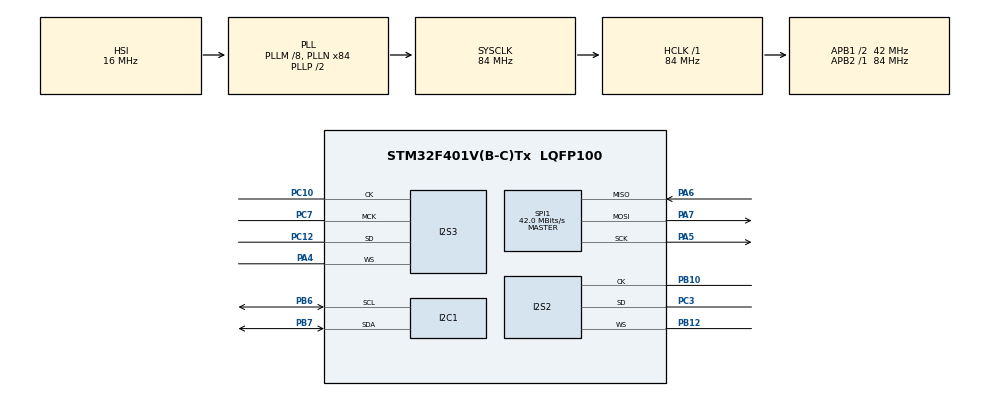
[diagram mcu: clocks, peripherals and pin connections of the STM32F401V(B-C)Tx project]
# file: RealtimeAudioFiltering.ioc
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Dma.Request0=SPI2_RX
Dma.Request1=SPI3_TX
Dma.SPI2_RX.0.Direction=DMA_PERIPH_TO_MEMORY
Dma.SPI2_RX.0.FIFOMode=DMA_FIFOMODE_DISABLE
Dma.SPI2_RX.0.Instance=DMA1_Stream3
Dma.SPI2_RX.0.MemDataAlignment=DMA_MDATAALIGN_HALFWORD
Dma.SPI2_RX.0.MemInc=DMA_MINC_ENABLE
Dma.SPI2_RX.0.Mode=DMA_CIRCULAR
Dma.SPI2_RX.0.PeriphDataAlignment=DMA_PDATAALIGN_HALFWORD
Dma.SPI2_RX.0.PeriphInc=DMA_PINC_DISABLE
Dma.SPI2_RX.0.Priority=DMA_PRIORITY_HIGH
Dma.SPI3_TX.1.Direction=DMA_MEMORY_TO_PERIPH
Dma.SPI3_TX.1.FIFOMode=DMA_FIFOMODE_DISABLE
Dma.SPI3_TX.1.Instance=DMA1_Stream5
Dma.SPI3_TX.1.MemDataAlignment=DMA_MDATAALIGN_HALFWORD
Dma.SPI3_TX.1.MemInc=DMA_MINC_ENABLE
Dma.SPI3_TX.1.Mode=DMA_CIRCULAR
Dma.SPI3_TX.1.PeriphDataAlignment=DMA_PDATAALIGN_HALFWORD
Dma.SPI3_TX.1.PeriphInc=DMA_PINC_DISABLE
Dma.SPI3_TX.1.Priority=DMA_PRIORITY_HIGH
I2S2.AudioFreq=I2S_AUDIOFREQ_48K
I2S2.CPOL=I2S_CPOL_LOW
I2S2.DataFormat=I2S_DATAFORMAT_24B
I2S2.ErrorAudioFreq=1.72 %
I2S2.FullDuplexMode=I2S_FULLDUPLEXMODE_DISABLE
I2S2.Instance=SPI$Index
I2S2.Mode=I2S_MODE_SLAVE_RX
I2S2.RealAudioFreq=48.828 KHz
I2S2.Standard=I2S_STANDARD_MSB
I2S2.VirtualMode=I2S_MODE_SLAVE
I2S3.AudioFreq=I2S_AUDIOFREQ_48K
I2S3.DataFormat=I2S_DATAFORMAT_24B
I2S3.ErrorAudioFreq=1.72 %
I2S3.FullDuplexMode=I2S_FULLDUPLEXMODE_DISABLE
I2S3.Instance=SPI$Index
I2S3.RealAudioFreq=48.828 KHz
I2S3.VirtualMode=I2S_MODE_MASTER
Mcu.Family=STM32F4
Mcu.Name=STM32F401V(B-C)Tx
Mcu.Package=LQFP100
NVIC.DMA1_Stream3_IRQn=true\:0\:0\:false\:false\:true\:false\:true\:true
NVIC.DMA1_Stream5_IRQn=true\:0\:0\:false\:false\:true\:false\:true\:true
NVIC.PriorityGroup=NVIC_PRIORITYGROUP_4
PA13.Mode=Serial_Wire
PA13.Signal=SYS_JTMS-SWDIO
PA14.Mode=Serial_Wire
PA14.Signal=SYS_JTCK-SWCLK
PA4.GPIO_Speed=GPIO_SPEED_FREQ_HIGH
PA4.Mode=Half_Duplex_Master
PA4.Signal=I2S3_WS
PA5.Mode=Full_Duplex_Master
PA5.Signal=SPI1_SCK
PA6.Mode=Full_Duplex_Master
PA6.Signal=SPI1_MISO
PA7.Mode=Full_Duplex_Master
PA7.Signal=SPI1_MOSI
PB10.GPIO_Speed=GPIO_SPEED_FREQ_HIGH
PB10.Mode=Half_Duplex_Slave
PB10.Signal=I2S2_CK
PB12.GPIO_Speed=GPIO_SPEED_FREQ_HIGH
PB12.Mode=Half_Duplex_Slave
PB12.Signal=I2S2_WS
PB6.Mode=I2C
PB6.Signal=I2C1_SCL
PB7.Mode=I2C
PB7.Signal=I2C1_SDA
PC10.GPIO_Speed=GPIO_SPEED_FREQ_HIGH
PC10.Mode=Half_Duplex_Master
PC10.Signal=I2S3_CK
PC12.GPIO_Speed=GPIO_SPEED_FREQ_HIGH
PC12.Mode=Half_Duplex_Master
PC12.Signal=I2S3_SD
PC3.GPIO_Speed=GPIO_SPEED_FREQ_HIGH
PC3.Mode=Half_Duplex_Slave
PC3.Signal=I2S2_SD
PC7.GPIO_Speed=GPIO_SPEED_FREQ_HIGH
PC7.Mode=Master_Clock_Activated
PC7.Signal=I2S3_MCK
PDM2PCM.CHANNEL1_bit_order=PDM_FILTER_BIT_ORDER_LSB
PDM2PCM.CHANNEL1_endianness=PDM_FILTER_ENDIANNESS_BE
PDM2PCM.CHANNEL1_high_pass_tap=2122358088
PDM2PCM.CHANNEL1_in_ptr_channels=1
PDM2PCM.CHANNEL1_mic_gain=0
PDM2PCM.CHANNEL1_out_ptr_channels=1
PH0\ -\ OSC_IN.Mode=HSE-External-Oscillator
PH0\ -\ OSC_IN.Signal=RCC_OSC_IN
PH1\ -\ OSC_OUT.Mode=HSE-External-Oscillator
PH1\ -\ OSC_OUT.Signal=RCC_OSC_OUT
ProjectManager.HeapSize=0x400
ProjectManager.StackSize=0x800
ProjectManager.TargetToolchain=STM32CubeIDE
RCC.48MHZClocksFreq_Value=42000000
RCC.AHBFreq_Value=84000000
RCC.APB1CLKDivider=RCC_HCLK_DIV2
RCC.APB1Freq_Value=42000000
RCC.APB1TimFreq_Value=84000000
RCC.APB2Freq_Value=84000000
RCC.APB2TimFreq_Value=84000000
RCC.CortexFreq_Value=84000000
RCC.HCLKFreq_Value=84000000
RCC.HSE_VALUE=8000000
RCC.HSI_VALUE=16000000
RCC.LSE_VALUE=32768
RCC.PLLI2SN=50
RCC.PLLM=8
RCC.PLLN=84
RCC.SYSCLKFreq_VALUE=84000000
RCC.SYSCLKSource=RCC_SYSCLKSOURCE_PLLCLK
RCC.VCOOutputFreq_Value=168000000
SPI1.CalculateBaudRate=42.0 MBits/s
SPI1.Direction=SPI_DIRECTION_2LINES
SPI1.Mode=SPI_MODE_MASTER
SPI1.VirtualType=VM_MASTER
VP_CRC_VS_CRC.Mode=CRC_Activate
VP_PDM2PCM_VS_PDM2PCM.Mode=PDM2PCM_Channel
board=custom

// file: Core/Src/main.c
/* USER CODE BEGIN Header */
/**
 ******************************************************************************
 * @file           : main.c
 * @brief          : Main program body
 ******************************************************************************
 * @attention
 *
 * Copyright (c) 2023 STMicroelectronics.
 * All rights reserved.
 *
 * This software is licensed under terms that can be found in the LICENSE file
 * in the root directory of this software component.
 * If no LICENSE file comes with this software, it is provided AS-IS.
 *
 ******************************************************************************
 */
/* USER CODE END Header */
#include "main.h"
#include "pdm2pcm.h"

/* USER CODE BEGIN Includes */

#include "stdbool.h"
#include "arm_math.h"
#include "rx_tx_manager.h"
#include "filters.h"

/* USER CODE END Includes */

CRC_HandleTypeDef hcrc;

I2C_HandleTypeDef hi2c1;

I2S_HandleTypeDef hi2s2;
I2S_HandleTypeDef hi2s3;
DMA_HandleTypeDef hdma_spi2_rx;
DMA_HandleTypeDef hdma_spi3_tx;

SPI_HandleTypeDef hspi1;

void SystemClock_Config(void);
void PeriphCommonClock_Config(void);
static void MX_GPIO_Init(void);
static void MX_DMA_Init(void);
static void MX_I2S2_Init(void);
static void MX_I2S3_Init(void);
static void MX_CRC_Init(void);
static void MX_I2C1_Init(void);
static void MX_SPI1_Init(void);

int main(void)
{

  /* MCU Configuration--------------------------------------------------------*/

  /* Reset of all peripherals, Initializes the Flash interface and the Systick. */
  HAL_Init();

  /* Configure the system clock */
  SystemClock_Config();

/* Configure the peripherals common clocks */
  PeriphCommonClock_Config();

  /* Initialize all configured peripherals */
  MX_GPIO_Init();
  MX_DMA_Init();
  MX_I2S2_Init();
  MX_I2S3_Init();
  MX_CRC_Init();
  MX_PDM2PCM_Init();
  MX_I2C1_Init();
  MX_SPI1_Init();
  /* USER CODE BEGIN 2 */

  // Se configura e inicializan todos los elementos
  // asociados a la transmisión y recepción de audio
  rx_tx_init(&hi2s2,&hi2s3);

  // Se inicializan los filtros a utilizar
  filters_init();

  /* USER CODE END 2 */

  /* Infinite loop */
    while (1)
    {

    /* USER CODE BEGIN 3 */

        // Se procesan todos los eventos de audio, de haber alguno.
        // Se llama al callback rx_tx_data_process_float_cb
        rx_tx_process();
    }
  /* USER CODE END 3 */
}

void SystemClock_Config(void)
{
  RCC_OscInitTypeDef RCC_OscInitStruct = {0};
  RCC_ClkInitTypeDef RCC_ClkInitStruct = {0};

  /** Configure the main internal regulator output voltage
  */
  __HAL_RCC_PWR_CLK_ENABLE();
  __HAL_PWR_VOLTAGESCALING_CONFIG(PWR_REGULATOR_VOLTAGE_SCALE2);

  /** Initializes the RCC Oscillators according to the specified parameters
  * in the RCC_OscInitTypeDef structure.
  */
  RCC_OscInitStruct.OscillatorType = RCC_OSCILLATORTYPE_HSI;
  RCC_OscInitStruct.HSIState = RCC_HSI_ON;
  RCC_OscInitStruct.HSICalibrationValue = RCC_HSICALIBRATION_DEFAULT;
  RCC_OscInitStruct.PLL.PLLState = RCC_PLL_ON;
  RCC_OscInitStruct.PLL.PLLSource = RCC_PLLSOURCE_HSI;
  RCC_OscInitStruct.PLL.PLLM = 8;
  RCC_OscInitStruct.PLL.PLLN = 84;
  RCC_OscInitStruct.PLL.PLLP = RCC_PLLP_DIV2;
  RCC_OscInitStruct.PLL.PLLQ = 4;
  if (HAL_RCC_OscConfig(&RCC_OscInitStruct) != HAL_OK)
  {
    Error_Handler();
  }

  /** Initializes the CPU, AHB and APB buses clocks
  */
  RCC_ClkInitStruct.ClockType = RCC_CLOCKTYPE_HCLK|RCC_CLOCKTYPE_SYSCLK
                              |RCC_CLOCKTYPE_PCLK1|RCC_CLOCKTYPE_PCLK2;
  RCC_ClkInitStruct.SYSCLKSource = RCC_SYSCLKSOURCE_PLLCLK;
  RCC_ClkInitStruct.AHBCLKDivider = RCC_SYSCLK_DIV1;
  RCC_ClkInitStruct.APB1CLKDivider = RCC_HCLK_DIV2;
  RCC_ClkInitStruct.APB2CLKDivider = RCC_HCLK_DIV1;

  if (HAL_RCC_ClockConfig(&RCC_ClkInitStruct, FLASH_LATENCY_2) != HAL_OK)
  {
    Error_Handler();
  }
}

void PeriphCommonClock_Config(void)
{
  RCC_PeriphCLKInitTypeDef PeriphClkInitStruct = {0};

  /** Initializes the peripherals clock
  */
  PeriphClkInitStruct.PeriphClockSelection = RCC_PERIPHCLK_I2S;
  PeriphClkInitStruct.PLLI2S.PLLI2SN = 50;
  PeriphClkInitStruct.PLLI2S.PLLI2SR = 2;
  if (HAL_RCCEx_PeriphCLKConfig(&PeriphClkInitStruct) != HAL_OK)
  {
    Error_Handler();
  }
}

static void MX_CRC_Init(void)
{

  hcrc.Instance = CRC;
  if (HAL_CRC_Init(&hcrc) != HAL_OK)
  {
    Error_Handler();
  }
  __HAL_CRC_DR_RESET(&hcrc);

}

static void MX_I2C1_Init(void)
{

  hi2c1.Instance = I2C1;
  hi2c1.Init.ClockSpeed = 100000;
  hi2c1.Init.DutyCycle = I2C_DUTYCYCLE_2;
  hi2c1.Init.OwnAddress1 = 0;
  hi2c1.Init.AddressingMode = I2C_ADDRESSINGMODE_7BIT;
  hi2c1.Init.DualAddressMode = I2C_DUALADDRESS_DISABLE;
  hi2c1.Init.OwnAddress2 = 0;
  hi2c1.Init.GeneralCallMode = I2C_GENERALCALL_DISABLE;
  hi2c1.Init.NoStretchMode = I2C_NOSTRETCH_DISABLE;
  if (HAL_I2C_Init(&hi2c1) != HAL_OK)
  {
    Error_Handler();
  }

}

static void MX_I2S2_Init(void)
{

  hi2s2.Instance = SPI2;
  hi2s2.Init.Mode = I2S_MODE_SLAVE_RX;
  hi2s2.Init.Standard = I2S_STANDARD_MSB;
  hi2s2.Init.DataFormat = I2S_DATAFORMAT_24B;
  hi2s2.Init.MCLKOutput = I2S_MCLKOUTPUT_DISABLE;
  hi2s2.Init.AudioFreq = I2S_AUDIOFREQ_48K;
  hi2s2.Init.CPOL = I2S_CPOL_LOW;
  hi2s2.Init.ClockSource = I2S_CLOCK_PLL;
  hi2s2.Init.FullDuplexMode = I2S_FULLDUPLEXMODE_DISABLE;
  if (HAL_I2S_Init(&hi2s2) != HAL_OK)
  {
    Error_Handler();
  }

}

static void MX_I2S3_Init(void)
{

  hi2s3.Instance = SPI3;
  hi2s3.Init.Mode = I2S_MODE_MASTER_TX;
  hi2s3.Init.Standard = I2S_STANDARD_PHILIPS;
  hi2s3.Init.DataFormat = I2S_DATAFORMAT_24B;
  hi2s3.Init.MCLKOutput = I2S_MCLKOUTPUT_ENABLE;
  hi2s3.Init.AudioFreq = I2S_AUDIOFREQ_48K;
  hi2s3.Init.CPOL = I2S_CPOL_LOW;
  hi2s3.Init.ClockSource = I2S_CLOCK_PLL;
  hi2s3.Init.FullDuplexMode = I2S_FULLDUPLEXMODE_DISABLE;
  if (HAL_I2S_Init(&hi2s3) != HAL_OK)
  {
    Error_Handler();
  }

}

static void MX_SPI1_Init(void)
{

  /* SPI1 parameter configuration*/
  hspi1.Instance = SPI1;
  hspi1.Init.Mode = SPI_MODE_MASTER;
  hspi1.Init.Direction = SPI_DIRECTION_2LINES;
  hspi1.Init.DataSize = SPI_DATASIZE_8BIT;
  hspi1.Init.CLKPolarity = SPI_POLARITY_LOW;
  hspi1.Init.CLKPhase = SPI_PHASE_1EDGE;
  hspi1.Init.NSS = SPI_NSS_SOFT;
  hspi1.Init.BaudRatePrescaler = SPI_BAUDRATEPRESCALER_2;
  hspi1.Init.FirstBit = SPI_FIRSTBIT_MSB;
  hspi1.Init.TIMode = SPI_TIMODE_DISABLE;
  hspi1.Init.CRCCalculation = SPI_CRCCALCULATION_DISABLE;
  hspi1.Init.CRCPolynomial = 10;
  if (HAL_SPI_Init(&hspi1) != HAL_OK)
  {
    Error_Handler();
  }

}

static void MX_DMA_Init(void)
{

  /* DMA controller clock enable */
  __HAL_RCC_DMA1_CLK_ENABLE();

  /* DMA interrupt init */
  /* DMA1_Stream3_IRQn interrupt configuration */
  HAL_NVIC_SetPriority(DMA1_Stream3_IRQn, 0, 0);
  HAL_NVIC_EnableIRQ(DMA1_Stream3_IRQn);
  /* DMA1_Stream5_IRQn interrupt configuration */
  HAL_NVIC_SetPriority(DMA1_Stream5_IRQn, 0, 0);
  HAL_NVIC_EnableIRQ(DMA1_Stream5_IRQn);

}

static void MX_GPIO_Init(void)
{

  /* GPIO Ports Clock Enable */
  __HAL_RCC_GPIOH_CLK_ENABLE();
  __HAL_RCC_GPIOC_CLK_ENABLE();
  __HAL_RCC_GPIOA_CLK_ENABLE();
  __HAL_RCC_GPIOB_CLK_ENABLE();

}

void Error_Handler(void)
{
    __disable_irq();
    while (1)
    {
    }
}
